# STM32H743 register map
File version: 1.9
CPU: CM7 r0p1, little endian, MPU, FPU, 4 interrupt priority bits
Registers are 32-bit, read-write, reset 0x0 unless marked. A register's access mark holds for its fields unless they carry their own. Offsets are from the block's base; [hi:lo] are bit positions; {n}, {i} and the like mark numbered series.

## RAMECC2 — ECC controller is associated to each RAM area
Base 0x48023000
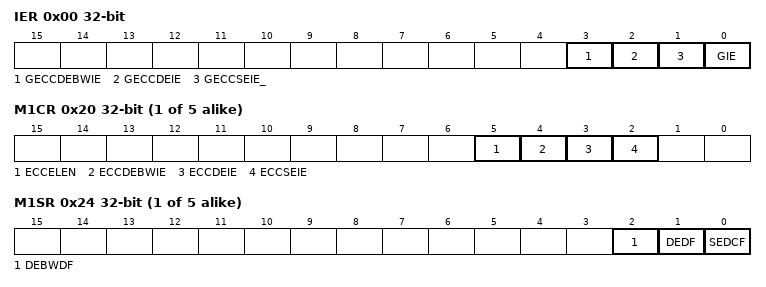
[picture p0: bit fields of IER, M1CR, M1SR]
0x00 IER — RAMECC interrupt enable register
  [3] GECCDEBWIE — Global ECC double error on byte write (BW) interrupt enable
  [2] GECCDEIE — Global ECC double error interrupt enable
  [1] GECCSEIE_ — Global ECC single error interrupt enable
  [0] GIE — Global interrupt enable
{0x0+0x20*i} M{i}CR (i=1..5) — RAMECC monitor x configuration register
  [5] ECCELEN — ECC error latching enable
  [4] ECCDEBWIE — ECC double error on byte write (BW) interrupt enable
  [3] ECCDEIE — ECC double error interrupt enable
  [2] ECCSEIE — ECC single error interrupt enable
{0x4+0x20*i} M{i}SR (i=1..5) — RAMECC monitor x status register
  [2] DEBWDF — ECC double error on byte write (BW) detected flag
  [1] DEDF — ECC double error detected flag
  [0] SEDCF — ECC single error detected and corrected flag
{0x8+0x20*i} M{i}FAR ro (i=1..4) — RAMECC monitor x failing address register
  [31:0] FADD — ECC error failing address
{0xC+0x20*i} M{i}FDRL ro (i=1..5) — RAMECC monitor x failing data low register
  [31:0] FDATAL — Failing data low
0x30 M1FDRH ro — RAMECC monitor x failing data high register
  [31:0] FDATAH — Failing data high (64-bit memory)
0x34 M1FECR — RAMECC monitor x failing ECC error code register
  [31:0] FEC — Failing error code
0x50 M2FDRH — RAMECC monitor x failing data high register
  [31:0] FDATAH — Failing data high (64-bit memory)
0x58 M2FECR — RAMECC monitor x failing ECC error code register
  [31:0] FEC — Failing error code
0x70 M3FDRH ro — RAMECC monitor x failing data high register
  [31:0] FDATAH — Failing data high (64-bit memory)
0x7C M3FECR ro — RAMECC monitor x failing ECC error code register
  [31:0] FEC — Failing error code
0x90 M4FDRH ro — RAMECC monitor x failing data high register
  [31:0] FDATAH — Failing data high (64-bit memory)
0x90 M4FECR ro (alternate view of M4FDRH) — RAMECC monitor x failing ECC error code register
  [31:0] FEC — Failing error code
0xA8 M5FAR — RAMECC monitor x failing address register
  [31:0] FADD — ECC error failing address
0xB0 M5FDRH ro — RAMECC monitor x failing data high register
  [31:0] FEC — Failing error code
0xB4 M5FECR ro — RAMECC monitor x failing ECC error code register
  [31:0] FEC — Failing error code

## RAMECC3 — ECC controller is associated to each RAM area
Base 0x58027000
Registers as RAMECC2, without M{n}CR (n=3..5), M{n}SR (n=3..5), M{n}FAR (n=3..5), M{n}FDRL (n=3..5), M{n}FDRH (n=3..5), M{n}FECR (n=3..5).

## DELAY_Block_SDMMC1
Base 0x52008000
Same registers: DELAY_Block_SDMMC2 0x48022800, DELAY_Block_QUADSPI 0x52006000
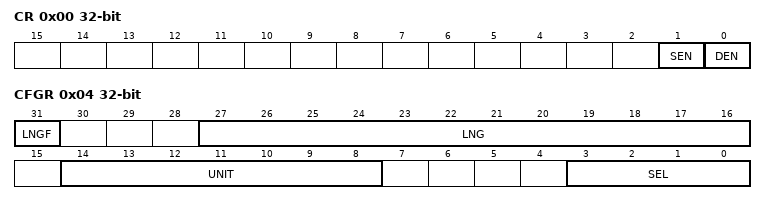
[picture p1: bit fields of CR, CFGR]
0x00 CR — DLYB control register
  [1] SEN — Sampler length enable bit
  [0] DEN — Delay block enable bit
0x04 CFGR — DLYB configuration register
  [31] LNGF — Length valid flag
  [27:16] LNG — Delay line length value
  [14:8] UNIT — Delay Defines the delay of a Unit delay cell
  [3:0] SEL — Select the phase for the Output clock

## DCMI — Digital camera interface
Base 0x48020000
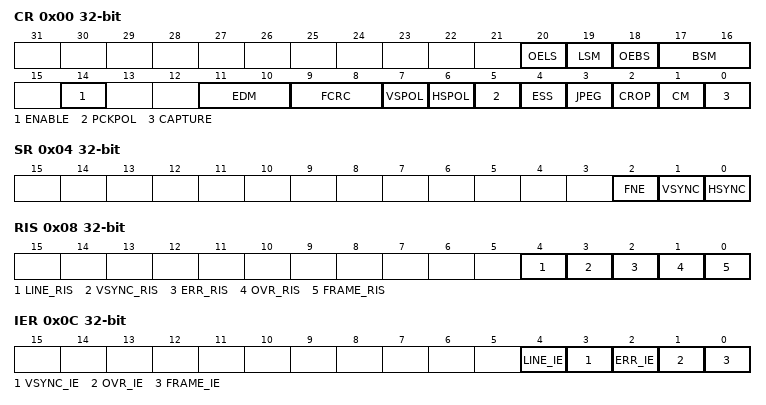
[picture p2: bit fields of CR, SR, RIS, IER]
0x00 CR — control register 1
  [20] OELS — Odd/Even Line Select (Line Select Start)
  [19] LSM — Line Select mode
  [18] OEBS — Odd/Even Byte Select (Byte Select Start)
  [17:16] BSM — Byte Select mode
  [14] ENABLE — DCMI enable
  [11:10] EDM — Extended data mode
  [9:8] FCRC — Frame capture rate control
  [7] VSPOL — Vertical synchronization polarity
  [6] HSPOL — Horizontal synchronization polarity
  [5] PCKPOL — Pixel clock polarity
  [4] ESS — Embedded synchronization select
  [3] JPEG — JPEG format
  [2] CROP — Crop feature
  [1] CM — Capture mode
  [0] CAPTURE — Capture enable
0x04 SR ro — status register
  [2] FNE — FIFO not empty
  [1] VSYNC
  [0] HSYNC
0x08 RIS ro — raw interrupt status register
  [4] LINE_RIS — Line raw interrupt status
  [3] VSYNC_RIS — VSYNC raw interrupt status
  [2] ERR_RIS — Synchronization error raw interrupt status
  [1] OVR_RIS — Overrun raw interrupt status
  [0] FRAME_RIS — Capture complete raw interrupt status
0x0C IER — interrupt enable register
  [4] LINE_IE — Line interrupt enable
  [3] VSYNC_IE — VSYNC interrupt enable
  [2] ERR_IE — Synchronization error interrupt enable
  [1] OVR_IE — Overrun interrupt enable
  [0] FRAME_IE — Capture complete interrupt enable
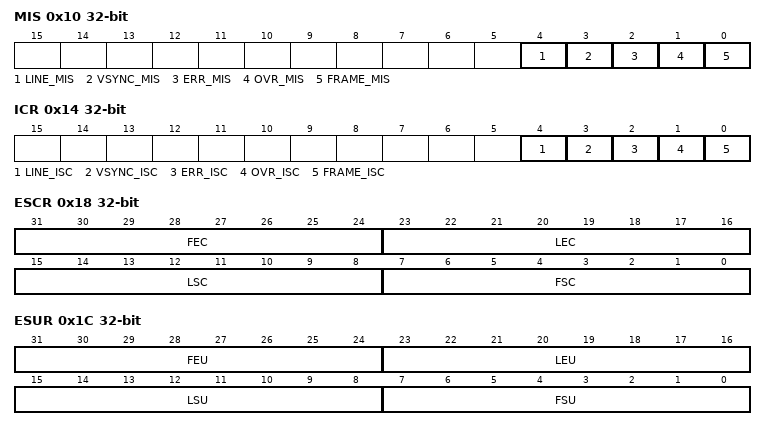
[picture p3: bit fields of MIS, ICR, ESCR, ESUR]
0x10 MIS ro — masked interrupt status register
  [4] LINE_MIS — Line masked interrupt status
  [3] VSYNC_MIS — VSYNC masked interrupt status
  [2] ERR_MIS — Synchronization error masked interrupt status
  [1] OVR_MIS — Overrun masked interrupt status
  [0] FRAME_MIS — Capture complete masked interrupt status
0x14 ICR wo — interrupt clear register
  [4] LINE_ISC — line interrupt status clear
  [3] VSYNC_ISC — Vertical synch interrupt status clear
  [2] ERR_ISC — Synchronization error interrupt status clear
  [1] OVR_ISC — Overrun interrupt status clear
  [0] FRAME_ISC — Capture complete interrupt status clear
0x18 ESCR — embedded synchronization code register
  [31:24] FEC — Frame end delimiter code
  [23:16] LEC — Line end delimiter code
  [15:8] LSC — Line start delimiter code
  [7:0] FSC — Frame start delimiter code
0x1C ESUR — embedded synchronization unmask register
  [31:24] FEU — Frame end delimiter unmask
  [23:16] LEU — Line end delimiter unmask
  [15:8] LSU — Line start delimiter unmask
  [7:0] FSU — Frame start delimiter unmask
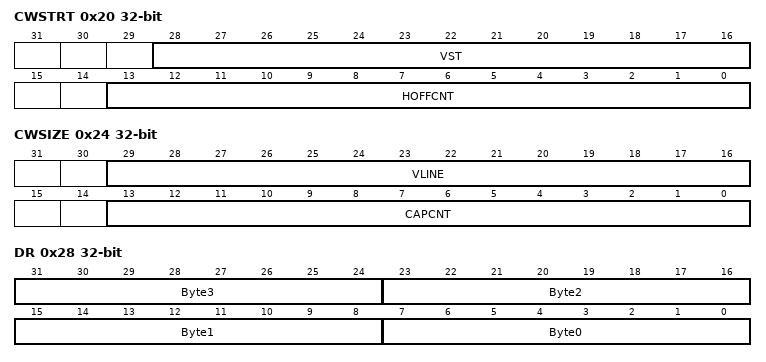
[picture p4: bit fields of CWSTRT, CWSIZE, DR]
0x20 CWSTRT — crop window start
  [28:16] VST — Vertical start line count
  [13:0] HOFFCNT — Horizontal offset count
0x24 CWSIZE — crop window size
  [29:16] VLINE — Vertical line count
  [13:0] CAPCNT — Capture count
0x28 DR ro — data register
  [8n+7:8n] Byte{n} (n=0..3) — Data byte {n}
